AUTOSAR XML (schema 4.0)
standard types defined: float32, float64, sint16, sint32, sint8, uint16, uint32, uint8, void, boolean
package /ImplDataTypes
  5 x impl type, all with category=TYPE_REFERENCE, implementation-data-type=uint8, type-emitter=RTE:
    HeightImpType
    InclineImpType
    MultiStateBtnType
    SlideImpType
    StepMotorStepImpType
package /MappingSets
  data type mapping set MappingSet
package /PortInterfaces/ClientServer
  client server interface CsIf_HeightMotor
    operation Move
      arg Step: type=StepMotorStepImpType, direction=IN
  client server interface CsIf_InclineMotor
    operation Move
      arg Step: type=StepMotorStepImpType, direction=IN
  client server interface CsIf_SlideMotor
    operation Move
      arg Step: type=StepMotorStepImpType, direction=IN
package /PortInterfaces/SenderReceiver
  sender receiver interface SrIf_SeatCtrlBtns
    data HeightBtnState: type=MultiStateBtnType
    data InclineBtnState: type=MultiStateBtnType
    data SlideBtnState: type=MultiStateBtnType
  sender receiver interface SrIf_SeatCtrlData
    data Height: type=HeightImpType
    data Incline: type=InclineImpType
    data Slide: type=SlideImpType
package /SoftwareComponents
  application sw component type ECU
    provide port ppSeatCtrlData: provided-interface=SrIf_SeatCtrlData
    behavior Ibhv_ECU: data-type-mapping=MappingSet, handle-termination-and-restart=NO-SUPPORT
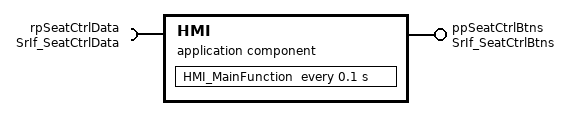
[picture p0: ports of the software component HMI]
  application sw component type HMI
    provide port ppSeatCtrlBtns: provided-interface=SrIf_SeatCtrlBtns
    require port rpSeatCtrlData: required-interface=SrIf_SeatCtrlData
    behavior Ibhv_HMI: data-type-mapping=MappingSet, handle-termination-and-restart=NO-SUPPORT
      timing event TE_HMI_MainFunction_100ms: start-on-event=HMI_MainFunction, period=0.1
      runnable HMI_MainFunction
        data-receive-point-by-arguments:
          access DRP_rpSeatCtrlData_Height: accessed-variable=rpSeatCtrlData.Height
          access DRP_rpSeatCtrlData_Incline: accessed-variable=rpSeatCtrlData.Incline
          access DRP_rpSeatCtrlData_Slide: accessed-variable=rpSeatCtrlData.Slide
        data-send-points:
          access DSP_ppSeatCtrlBtns_HeightBtnState: accessed-variable=ppSeatCtrlBtns.HeightBtnState
          access DSP_ppSeatCtrlBtns_InclineBtnState: accessed-variable=ppSeatCtrlBtns.InclineBtnState
          access DSP_ppSeatCtrlBtns_SlideBtnState: accessed-variable=ppSeatCtrlBtns.SlideBtnState
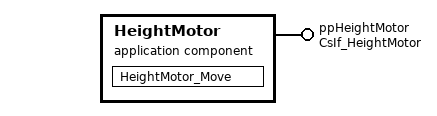
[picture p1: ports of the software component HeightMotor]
  application sw component type HeightMotor
    provide port ppHeightMotor: provided-interface=CsIf_HeightMotor
    behavior Ibhv_HeightMotor: data-type-mapping=MappingSet, handle-termination-and-restart=NO-SUPPORT
      operation invoked event OIE_ppHeightMotor_Move: start-on-event=HeightMotor_Move, operation=ppHeightMotor.Move
      runnable HeightMotor_Move
  6 x swc implementation, all with programming-language=C, sw-version=1.0.0, vendor-id=255:
    Impl_ECU: behavior=Ibhv_ECU
      code-descriptors:
        code Code: artifact-descriptors=autosar-engineering-object={short-label=SWC.c, category=SWSRC}
      resource consumption ResourceConsumption
    Impl_HMI: behavior=Ibhv_HMI
      code-descriptors:
        code Code: artifact-descriptors=autosar-engineering-object={short-label=SWC.c, category=SWSRC}
      resource consumption ResourceConsumption
    Impl_HeightMotor: behavior=Ibhv_HeightMotor
      code-descriptors:
        code Code: artifact-descriptors=autosar-engineering-object={short-label=SWC.c, category=SWSRC}
      resource consumption ResourceConsumption
    Impl_InclineMotor: behavior=Ibhv_InclineMotor
      code-descriptors:
        code Code: artifact-descriptors=autosar-engineering-object={short-label=SWC.c, category=SWSRC}
      resource consumption ResourceConsumption
    Impl_SeatMgr: behavior=Ibhv_SeatMgr
      code-descriptors:
        code Code: artifact-descriptors=autosar-engineering-object={short-label=SWC.c, category=SWSRC}
      resource consumption ResourceConsumption
    Impl_SlideMotor: behavior=Ibhv_SlideMotor
      code-descriptors:
        code Code: artifact-descriptors=autosar-engineering-object={short-label=SWC.c, category=SWSRC}
      resource consumption ResourceConsumption
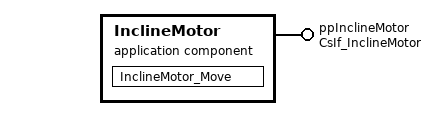
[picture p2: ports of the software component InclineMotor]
  application sw component type InclineMotor
    provide port ppInclineMotor: provided-interface=CsIf_InclineMotor
    behavior Ibhv_InclineMotor: data-type-mapping=MappingSet, handle-termination-and-restart=NO-SUPPORT
      operation invoked event OIE_ppInclineMotor_Move: start-on-event=InclineMotor_Move, operation=ppInclineMotor.Move
      runnable InclineMotor_Move
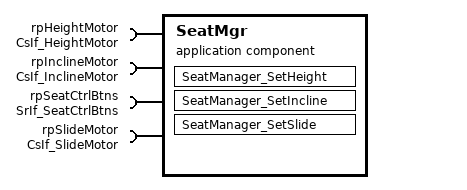
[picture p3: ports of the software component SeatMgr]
  application sw component type SeatMgr
    4 x require port:
      rpHeightMotor: required-interface=CsIf_HeightMotor
      rpInclineMotor: required-interface=CsIf_InclineMotor
      rpSeatCtrlBtns: required-interface=SrIf_SeatCtrlBtns
      rpSlideMotor: required-interface=CsIf_SlideMotor
    behavior Ibhv_SeatMgr: data-type-mapping=MappingSet, handle-termination-and-restart=NO-SUPPORT
      data received event DRE_rpSeatCtrlBtns_HeightBtnState: start-on-event=SeatManager_SetHeight, data=rpSeatCtrlBtns.HeightBtnState
      data received event DRE_rpSeatCtrlBtns_InclineBtnState: start-on-event=SeatManager_SetIncline, data=rpSeatCtrlBtns.InclineBtnState
      data received event DRE_rpSeatCtrlBtns_SlideBtnState: start-on-event=SeatManager_SetSlide, data=rpSeatCtrlBtns.SlideBtnState
      runnable SeatManager_SetHeight
        data-receive-point-by-arguments:
          access DRP_rpSeatCtrlBtns_HeightBtnState: accessed-variable=rpSeatCtrlBtns.HeightBtnState
        sync call SCP_rpHeightMotor_Move: operation=rpHeightMotor.Move, timeout=0.0
      runnable SeatManager_SetIncline
        data-receive-point-by-arguments:
          access DRP_rpSeatCtrlBtns_InclineBtnState: accessed-variable=rpSeatCtrlBtns.InclineBtnState
        sync call SCP_rpInclineMotor_Move: operation=rpInclineMotor.Move, timeout=0.0
      runnable SeatManager_SetSlide
        data-receive-point-by-arguments:
          access DRP_rpSeatCtrlBtns_SlideBtnState: accessed-variable=rpSeatCtrlBtns.SlideBtnState
        sync call SCP_rpSlideMotor_Move: operation=rpSlideMotor.Move, timeout=0.0
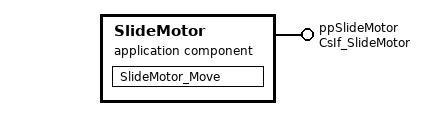
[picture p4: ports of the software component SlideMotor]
  application sw component type SlideMotor
    provide port ppSlideMotor: provided-interface=CsIf_SlideMotor
    behavior Ibhv_SlideMotor: data-type-mapping=MappingSet, handle-termination-and-restart=NO-SUPPORT
      operation invoked event OIE_ppSlideMotor_Move: start-on-event=SlideMotor_Move, operation=ppSlideMotor.Move
      runnable SlideMotor_Move
package /Compositions
  composition sw component type SR in SeatComposition
    6 x component:
      ECU: type=ECU
      HMI: type=HMI
      HeightMotor: type=HeightMotor
      InclineMotor: type=InclineMotor
      SeatMgr: type=SeatMgr
      SlideMotor: type=SlideMotor
    connect HMI.ppSeatCtrlBtns -> SeatMgr.rpSeatCtrlBtns
    connect HeightMotor.ppHeightMotor -> SeatMgr.rpHeightMotor
    connect InclineMotor.ppInclineMotor -> SeatMgr.rpInclineMotor
    connect SlideMotor.ppSlideMotor -> SeatMgr.rpSlideMotor
